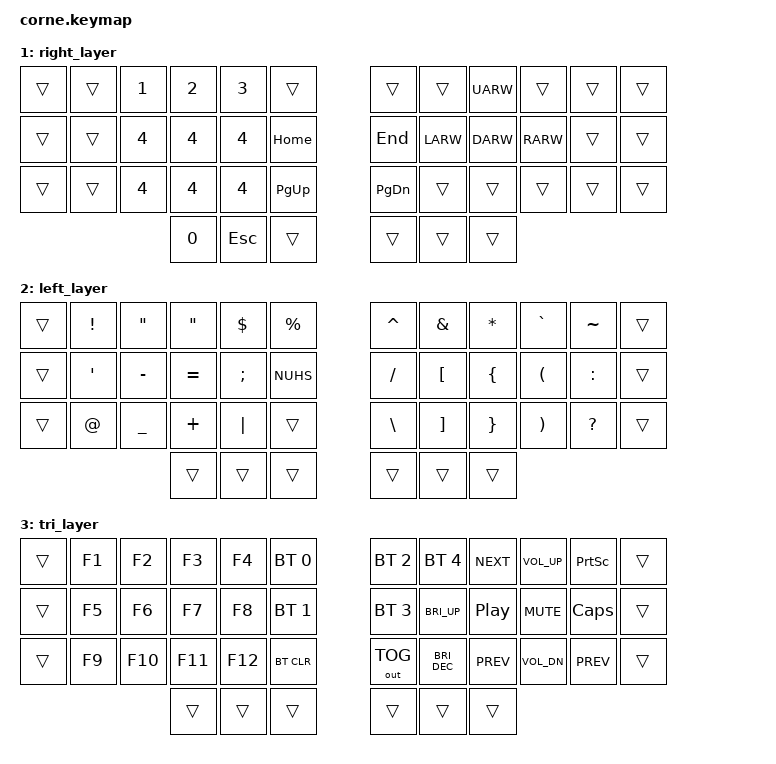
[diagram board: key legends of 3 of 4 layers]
// Copyright (c) 2022 The ZMK Contributors
// SPDX-License-Identifier: MIT

#include <behaviors.dtsi>
#include <dt-bindings/zmk/keys.h>
#include <dt-bindings/zmk/bt.h>
#include <dt-bindings/zmk/outputs.h>

// Home row mods macro
#define WHRML(k2,k3,k4) &ht LALT k2  &ht LGUI k3  &ht LCTRL k4
#define WHRMR(k1,k2,k3) &ht RCTRL k1  &ht RGUI k2  &ht RALT k3

#define WIN 0
#define RIG 1
#define LEF 2
#define TRI 3

/ {
    behaviors {
        ht: hold_tap {
            label = "hold_tap";
            compatible = "zmk,behavior-hold-tap";
            #binding-cells = <2>;
            flavor = "tap-preferred";
            tapping-term-ms = <220>;
            quick-tap-ms = <150>;
            global-quick-tap;
            bindings = <&kp>, <&kp>;
        };
    };

    conditional_layers {
        compatible = "zmk,conditional-layers";
        tri_layer {
            if-layers = <RIG LEF>;
            then-layer = <TRI>;
        };
    };

    keymap {
        compatible = "zmk,keymap";
        default_layer {
            bindings = <
        //╭──────────┬──────────┬──────────┬──────────┬──────────╮   ╭──────────┬──────────┬──────────┬──────────┬──────────╮
        //│  Q       │  W       │  E       │  R       │  T       │   │  Y       │  U       │  I       │  O       │  P       │
    &trans  &kp Q      &kp W      &kp E      &kp R      &kp T          &kp Y      &kp U      &kp I      &kp O      &kp P        &trans
        //├──────────┼──────────┼──────────┼──────────┼──────────┤   ├──────────┼──────────┼──────────┼──────────┼──────────┤
        //│  A       │  S       │  D       │  F       │  G       │   │  H       │  J       │  K       │  L       │BACKSPACE │
    &trans  &kp A    WHRML(S,         D,         F)     &kp G          &kp H      WHRMR(J,        K,         L)   &kp BSPC      &trans
        //├──────────┼──────────┼──────────┼──────────┼──────────┤   ├──────────┼──────────┼──────────┼──────────┼──────────┤
        //│  Z       │  X       │  C       │  V       │  B       │   │  N       │  M       │ , <      │ . >      │ ENTER    │
    &trans  &kp Z      &kp X      &kp C      &kp V      &kp B          &kp N      &kp M      &kp COMMA  &kp DOT    &kp ENTER    &trans
        //╰──────────┴──────────┴──────────┼──────────┼──────────┤   ├──────────┼──────────┼──────────┴──────────┴──────────╯
                                 &kp LSHIFT &lt (LEF DEL)  &kp ALT    &kp TAB  &lt (RIG SPACE) &kp LCTRL
        //                                 ╰──────────┴──────────╯   ╰──────────┴──────────╯
            >;
        };

        right_layer {
            bindings = <
        //╭──────────┬──────────┬──────────┬──────────┬──────────╮   ╭──────────┬──────────┬──────────┬──────────┬──────────╮
        //│          │ 1        │  2       │ 3        │          │   │          │          │ UP       │          │          │
    &trans   &trans    &kp N1      &kp N2    &kp N3     &trans         &trans     &trans     &kp UARW     &trans      &trans      &trans
        //├──────────┼──────────┼──────────┼──────────┼──────────┤   ├──────────┼──────────┼──────────┼──────────┼──────────┤
        //│          │ 4        │ 5        │ 6        │ HOME     |   | END     │ LEFT      │ DOWN     │ RIGHT    │          │
    &trans  &trans     &kp N4     &kp N4     &kp N4     &kp HOME       &kp END   &kp LARW    &kp DARW   &kp RARW   &trans       &trans
        //├──────────┼──────────┼──────────┼──────────┼──────────┤   ├──────────┼──────────┼──────────┼──────────┼──────────┤
        //│          │ 7        │ 8        │ 9        │ PAGE UP  │   │ PAGE DN  │          │          │          │          │
    &trans  &trans     &kp N4     &kp N4     &kp N4     &kp PG_UP      &kp PG_DN  &trans     &trans     &trans     &trans     &trans
        //╰──────────┴──────────┴──────────┼──────────┼──────────┤   ├──────────┼──────────┼──────────┴──────────┴──────────╯
                                    &kp N0  &kp ESC        &trans     &trans     &trans      &trans
        //                                 ╰──────────┴──────────╯   ╰──────────┴──────────╯
            >;
        };

        left_layer {
            bindings = <
        //╭──────────┬──────────┬──────────┬──────────┬──────────╮   ╭──────────┬──────────┬──────────┬──────────┬──────────╮
        //│  !       │  "       │  "       │  $       │  %       │   │  ^       │  &       │  *       │  `       │  ~       │
    &trans  &kp EXCL   &kp DQT    &kp DQT    &kp DLLR   &kp PRCNT      &kp CARET  &kp AMPS   &kp ASTRK  &kp GRAVE   &kp TILDE   &trans
        //├──────────┼──────────┼──────────┼──────────┼──────────┤   ├──────────┼──────────┼──────────┼──────────┼──────────┤
        //│  '       │ -        │  =       │ ;        │  #       │   │   /      │   [      │  {       │  (       │     :    │
    &trans  &kp SQT   &kp MINUS  &kp EQUAL  &kp SEMI     &kp NUHS      &kp FSLH   &kp LBKT   &kp LBRC   &kp LPAR   &kp COLON     &trans
        //├──────────┼──────────┼──────────┼──────────┼──────────┤   ├──────────┼──────────┼──────────┼──────────┼──────────┤
        //│   @      │ _        │  +       │  │       │          │   │    \     │   ]      │  }       │  )       │   ?      │
    &trans  &kp AT     &kp UNDER  &kp PLUS   &kp PIPE    &trans         &kp BSLH  &kp RBKT   &kp RBRC   &kp RPAR  &kp QMARK     &trans
        //╰──────────┴──────────┴──────────┼──────────┼──────────┤   ├──────────┼──────────┼──────────┴──────────┴──────────╯
                                 &trans     &trans     &trans         &trans     &trans      &trans
        //                                 ╰──────────┴──────────╯   ╰──────────┴──────────╯
            >;
        };

        tri_layer {
            bindings = <
        //╭──────────┬──────────┬──────────┬───────────┬────────────╮   ╭────────────┬────────────┬──────────┬───────────┬──────────╮
        //│  F1      │  F2      │  F3      │  F4       │ PROFILE 0  │   │ PROFILE 2  │ PROFILE 4  │ NEXTSONG │ VOL UP    │PRINT SCRN│
    &trans  &kp F1     &kp F2     &kp F3     &kp F4     &bt BT_SEL 0     &bt BT_SEL 2 &bt BT_SEL 4  &kp C_NEXT&kp C_VOL_UP &kp PSCRN    &trans
        //├──────────┼──────────┼──────────┼───────────┼────────────┤   ├────────────┼────────────┼──────────┤───────────┼──────────┤
        //│  F5      │  F6      │  F7      │  F8       │ PROFILE 1  │   │ PROFILE 3  │INC BRIGHT  │PAUSEMUSIC│ VOL MUTE  │ CAPSLOCK │
    &trans  &kp F5     &kp F6     &kp F7     &kp F8     &bt BT_SEL 1     &bt BT_SEL 3 &kp C_BRI_UP &kp C_PP   &kp C_MUTE   &kp CAPS     &trans
        //├──────────┼──────────┼──────────┼───────────┼────────────┤   ├────────────┼────────────┼──────────┤───────────┼──────────┤
        //│  F9      │  F10     │  F11     │  F12      │  CLEAR BT  │   │TOGGLEOUT   │DEC BRIGHT  │ PREVSONG │  VOL DOWN │ PREVSONG │
    &trans  &kp F9     &kp F10    &kp F11    &kp F12     &bt BT_CLR      &out OUT_TOG &kp C_BRI_DEC &kp C_PREV&kp C_VOL_DN &kp C_PREV  &trans
        //╰──────────┴──────────┴──────────┼───────────┼────────────┤   ├────────────┼────────────┼──────────┴───────────┴──────────╯
                                 &trans     &trans     &trans         &trans     &trans      &trans
        //                                  ╰───────────┴──────────╯   ╰──────────┴────────────╯
            >;
        };
    };
};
